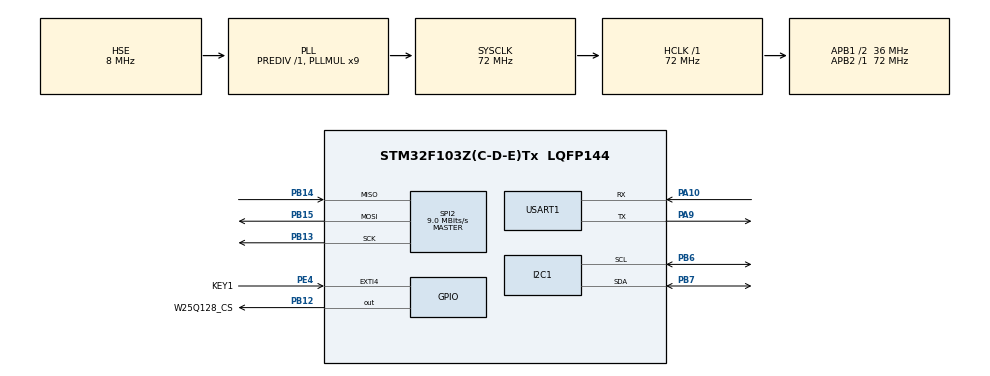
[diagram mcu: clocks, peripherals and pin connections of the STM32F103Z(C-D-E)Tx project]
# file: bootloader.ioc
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Mcu.Family=STM32F1
Mcu.Name=STM32F103Z(C-D-E)Tx
Mcu.Package=LQFP144
NVIC.EXTI4_IRQn=true\:4\:0\:true\:false\:true\:true\:true\:true
NVIC.PriorityGroup=NVIC_PRIORITYGROUP_4
NVIC.USART1_IRQn=true\:5\:0\:true\:false\:true\:true\:true\:true
OSC_IN.Mode=HSE-External-Oscillator
OSC_IN.Signal=RCC_OSC_IN
OSC_OUT.Mode=HSE-External-Oscillator
OSC_OUT.Signal=RCC_OSC_OUT
PA10.Mode=Asynchronous
PA10.Signal=USART1_RX
PA13.Mode=Serial_Wire
PA13.Signal=SYS_JTMS-SWDIO
PA14.Mode=Serial_Wire
PA14.Signal=SYS_JTCK-SWCLK
PA9.Mode=Asynchronous
PA9.Signal=USART1_TX
PB12.GPIO_Label=W25Q128_CS
PB12.GPIO_Speed=GPIO_SPEED_FREQ_HIGH
PB12.PinState=GPIO_PIN_SET
PB12.Signal=GPIO_Output
PB13.Mode=Full_Duplex_Master
PB13.Signal=SPI2_SCK
PB14.Mode=Full_Duplex_Master
PB14.Signal=SPI2_MISO
PB15.Mode=Full_Duplex_Master
PB15.Signal=SPI2_MOSI
PB6.Mode=I2C
PB6.Signal=I2C1_SCL
PB7.Mode=I2C
PB7.Signal=I2C1_SDA
PC14-OSC32_IN.Mode=LSE-External-Oscillator
PC14-OSC32_IN.Signal=RCC_OSC32_IN
PC15-OSC32_OUT.Mode=LSE-External-Oscillator
PC15-OSC32_OUT.Signal=RCC_OSC32_OUT
PE4.GPIO_Label=KEY1
PE4.GPIO_ModeDefaultEXTI=GPIO_MODE_IT_FALLING
PE4.GPIO_PuPd=GPIO_PULLUP
PE4.Signal=GPXTI4
ProjectManager.HeapSize=0x200
ProjectManager.StackSize=0x400
ProjectManager.TargetToolchain=MDK-ARM V5.32
RCC.AHBFreq_Value=72000000
RCC.APB1CLKDivider=RCC_HCLK_DIV2
RCC.APB1Freq_Value=36000000
RCC.APB1TimFreq_Value=72000000
RCC.APB2Freq_Value=72000000
RCC.APB2TimFreq_Value=72000000
RCC.HCLKFreq_Value=72000000
RCC.PLLMUL=RCC_PLL_MUL9
RCC.PLLSourceVirtual=RCC_PLLSOURCE_HSE
RCC.SYSCLKFreq_VALUE=72000000
RCC.SYSCLKSource=RCC_SYSCLKSOURCE_PLLCLK
RCC.USBFreq_Value=72000000
SPI2.BaudRatePrescaler=SPI_BAUDRATEPRESCALER_4
SPI2.CalculateBaudRate=9.0 MBits/s
SPI2.Direction=SPI_DIRECTION_2LINES
SPI2.Mode=SPI_MODE_MASTER
SPI2.VirtualType=VM_MASTER
USART1.VirtualMode=VM_ASYNC
board=custom

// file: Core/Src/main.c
/* USER CODE BEGIN Header */
/**
  ******************************************************************************
  * @file           : main.c
  * @brief          : Main program body
  ******************************************************************************
  * @attention
  *
  * Copyright (c) 2026 STMicroelectronics.
  * All rights reserved.
  *
  * This software is licensed under terms that can be found in the LICENSE file
  * in the root directory of this software component.
  * If no LICENSE file comes with this software, it is provided AS-IS.
  *
  ******************************************************************************
  */
/* USER CODE END Header */
#include "main.h"
#include "i2c.h"
#include "spi.h"
#include "usart.h"
#include "gpio.h"

/* USER CODE BEGIN Includes */
//#include "App_bootloader.h"
#include "Int_w25q128.h"
#include "App_bootloader.h"
/* USER CODE END Includes */

void SystemClock_Config(void);
/* USER CODE BEGIN PFP */
extern uint16_t uart_rec_total_len;
/* USER CODE END PFP */

/* USER CODE BEGIN 0 */
// #define REC_BUFF_LEN   32
/* USER CODE END 0 */

int main(void)
{

  /* MCU Configuration--------------------------------------------------------*/

  /* Reset of all peripherals, Initializes the Flash interface and the Systick. */
  HAL_Init();

  /* Configure the system clock */
  SystemClock_Config();

  /* Initialize all configured peripherals */
  MX_GPIO_Init();
  MX_USART1_UART_Init();
  MX_I2C1_Init();
  MX_SPI2_Init();
  /* USER CODE BEGIN 2 */

  __HAL_RCC_I2C1_FORCE_RESET();
  HAL_Delay(2);
  __HAL_RCC_I2C1_RELEASE_RESET();
  //重新初始化一下I2C
  MX_I2C1_Init();

  //1.检查更新状态
  App_bootloader_check_update();

  //2.判断是否进入默认程序  恢复出厂设置
  App_bootloader_check_default();

  //3.根据状态进行更新
  App_bootloader_update();

  //4.跳转到App
  App_bootloader_jump_app();

/*  调试I2C读写是否有问题的代码
HAL_StatusTypeDef write_status, read_status;
// 1. 写入并获取状态
write_status = HAL_I2C_Mem_Write(&hi2c1, W24C02_ADDR, 0x00, I2C_MEMADD_SIZE_8BIT, (uint8_t *)"123456", 6, 100);
if(write_status == HAL_OK) {
    printf("I2C Write Success!\r\n");
} else {
    printf("I2C Write Failed! Error Code: %d\r\n", write_status); // 1: ERROR, 2: BUSY, 3: TIMEOUT
}

HAL_Delay(5);

// 2. 读取并获取状态
uint8_t buff[10] = {0};
read_status = HAL_I2C_Mem_Read(&hi2c1, W24C02_ADDR_R, 0x00, I2C_MEMADD_SIZE_8BIT, buff, 6, 100);
if(read_status == HAL_OK) {
    printf("I2C Read Success! buff: %s\r\n", buff);
} else {
    printf("I2C Read Failed! Error Code: %d\r\n", read_status);
}
*/

  /* USER CODE END 2 */

  /* Infinite loop */
  while (1)
  {

  }
}

void SystemClock_Config(void)
{
  RCC_OscInitTypeDef RCC_OscInitStruct = {0};
  RCC_ClkInitTypeDef RCC_ClkInitStruct = {0};

  /** Initializes the RCC Oscillators according to the specified parameters
  * in the RCC_OscInitTypeDef structure.
  */
  RCC_OscInitStruct.OscillatorType = RCC_OSCILLATORTYPE_HSE;
  RCC_OscInitStruct.HSEState = RCC_HSE_ON;
  RCC_OscInitStruct.HSEPredivValue = RCC_HSE_PREDIV_DIV1;
  RCC_OscInitStruct.HSIState = RCC_HSI_ON;
  RCC_OscInitStruct.PLL.PLLState = RCC_PLL_ON;
  RCC_OscInitStruct.PLL.PLLSource = RCC_PLLSOURCE_HSE;
  RCC_OscInitStruct.PLL.PLLMUL = RCC_PLL_MUL9;
  if (HAL_RCC_OscConfig(&RCC_OscInitStruct) != HAL_OK)
  {
    Error_Handler();
  }

  /** Initializes the CPU, AHB and APB buses clocks
  */
  RCC_ClkInitStruct.ClockType = RCC_CLOCKTYPE_HCLK|RCC_CLOCKTYPE_SYSCLK
                              |RCC_CLOCKTYPE_PCLK1|RCC_CLOCKTYPE_PCLK2;
  RCC_ClkInitStruct.SYSCLKSource = RCC_SYSCLKSOURCE_PLLCLK;
  RCC_ClkInitStruct.AHBCLKDivider = RCC_SYSCLK_DIV1;
  RCC_ClkInitStruct.APB1CLKDivider = RCC_HCLK_DIV2;
  RCC_ClkInitStruct.APB2CLKDivider = RCC_HCLK_DIV1;

  if (HAL_RCC_ClockConfig(&RCC_ClkInitStruct, FLASH_LATENCY_2) != HAL_OK)
  {
    Error_Handler();
  }
}

void Error_Handler(void)
{
  __disable_irq();
  while (1)
  {
  }
}
